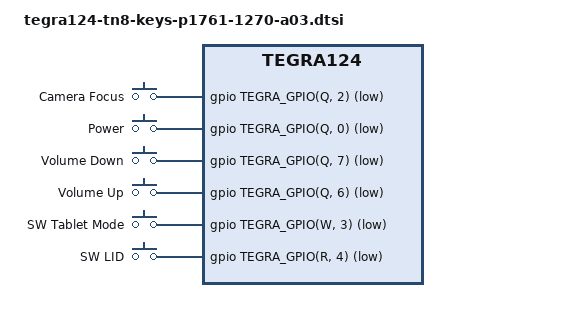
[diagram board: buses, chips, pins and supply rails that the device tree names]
#include <dt-bindings/gpio/tegra-gpio.h>
#include <dt-bindings/input/input.h>

/ {
	gpio-keys {
		compatible = "gpio-keys";

		camera_focus {
			label = "Camera Focus";
			gpios = <&gpio TEGRA_GPIO(Q, 2) GPIO_ACTIVE_LOW>;
			linux,code = <KEY_CAMERA_FOCUS>;
		};

		power {
			label = "Power";
			gpios = <&gpio TEGRA_GPIO(Q, 0) GPIO_ACTIVE_LOW>;
			linux,code = <KEY_POWER>;
			gpio-key,wakeup;
		};

		volume_down {
			label = "Volume Down";
			gpios = <&gpio TEGRA_GPIO(Q, 7) GPIO_ACTIVE_LOW>;
			linux,code = <KEY_VOLUMEDOWN>;
		};

		volume_up {
			label = "Volume Up";
			gpios = <&gpio TEGRA_GPIO(Q, 6) GPIO_ACTIVE_LOW>;
			linux,code = <KEY_VOLUMEUP>;
		};

		/* SW_TABLET_MODE switch is used for stylus pen detection
		 * when SW_TABLET_MODE = 1, pen is inserted
		 */
		sw_tablet_mode {
			label = "SW Tablet Mode";
			gpios = <&gpio TEGRA_GPIO(W, 3) GPIO_ACTIVE_LOW>;
			linux,code = <SW_TABLET_MODE>;
			linux,input-type = <EV_SW>;
			gpio-key,wakeup;
		};
		sw_lid {
			label = "SW LID";
			gpios = <&gpio TEGRA_GPIO(R, 4) GPIO_ACTIVE_LOW>;
			linux,code = <SW_LID>;
			linux,input-type = <EV_SW>;
			gpio-key,wakeup;
			debounce-interval = <300>;
		};
	};
};
